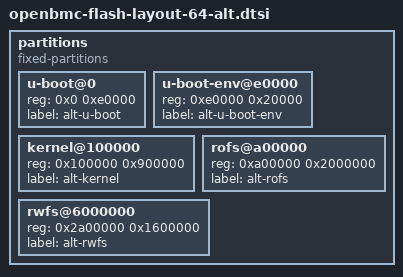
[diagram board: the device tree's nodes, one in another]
// SPDX-License-Identifier: GPL-2.0+
/*
 * Copyright (C) 2020 Bytedance.
 */

partitions {
	compatible = "fixed-partitions";
	#address-cells = <1>;
	#size-cells = <1>;

	u-boot@0 {
		reg = <0x0 0xe0000>; // 896KB
		label = "alt-u-boot";
	};

	u-boot-env@e0000 {
		reg = <0xe0000 0x20000>; // 128KB
		label = "alt-u-boot-env";
	};

	kernel@100000 {
		reg = <0x100000 0x900000>; // 9MB
		label = "alt-kernel";
	};

	rofs@a00000 {
		reg = <0xa00000 0x2000000>; // 32MB
		label = "alt-rofs";
	};

	rwfs@6000000 {
		reg = <0x2a00000 0x1600000>; // 22MB
		label = "alt-rwfs";
	};
};
